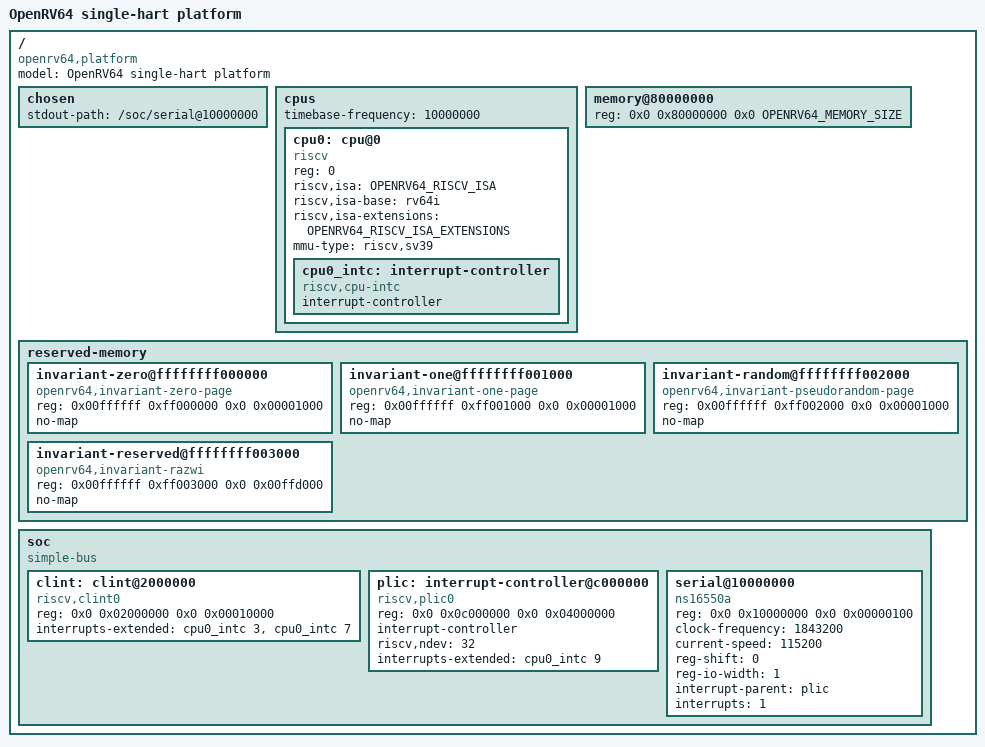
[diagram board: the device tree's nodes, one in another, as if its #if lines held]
/dts-v1/;

#ifndef OPENRV64_MEMORY_SIZE
#define OPENRV64_MEMORY_SIZE 0x10000000
#endif

#ifndef OPENRV64_HART_COUNT
#define OPENRV64_HART_COUNT 1
#endif

#if OPENRV64_HART_COUNT != 1 && OPENRV64_HART_COUNT != 2 && OPENRV64_HART_COUNT != 4
#error OPENRV64_HART_COUNT must be 1, 2, or 4
#endif

#if defined(OPENRV64_ZBB) && defined(OPENRV64_ZICCLSM)
#define OPENRV64_RISCV_ISA "rv64ima_svade_zbb_zicclsm_zicsr_zifencei"
#define OPENRV64_RISCV_ISA_EXTENSIONS "i", "m", "a", "svade", "zbb", "zicclsm", "zicsr", "zifencei"
#elif defined(OPENRV64_ZBB)
#define OPENRV64_RISCV_ISA "rv64ima_svade_zbb_zicsr_zifencei"
#define OPENRV64_RISCV_ISA_EXTENSIONS "i", "m", "a", "svade", "zbb", "zicsr", "zifencei"
#elif defined(OPENRV64_ZICCLSM)
#define OPENRV64_RISCV_ISA "rv64ima_svade_zicclsm_zicsr_zifencei"
#define OPENRV64_RISCV_ISA_EXTENSIONS "i", "m", "a", "svade", "zicclsm", "zicsr", "zifencei"
#else
#define OPENRV64_RISCV_ISA "rv64ima_svade_zicsr_zifencei"
#define OPENRV64_RISCV_ISA_EXTENSIONS "i", "m", "a", "svade", "zicsr", "zifencei"
#endif

/ {
    #address-cells = <2>;
    #size-cells = <2>;
    compatible = "openrv64,platform";
#if OPENRV64_HART_COUNT == 4
    model = "OpenRV64 four-hart platform";
#elif OPENRV64_HART_COUNT == 2
    model = "OpenRV64 two-hart platform";
#else
    model = "OpenRV64 single-hart platform";
#endif

    chosen {
        stdout-path = "/soc/serial@10000000";
#if OPENRV64_HART_COUNT > 1
        opensbi-config {
            compatible = "opensbi,config";
            cold-boot-harts = <&cpu0>;
        };
#endif
    };

    cpus {
        #address-cells = <1>;
        #size-cells = <0>;
        timebase-frequency = <10000000>;

        cpu0: cpu@0 {
            device_type = "cpu";
            reg = <0>;
            status = "okay";
            compatible = "riscv";
            riscv,isa = OPENRV64_RISCV_ISA;
            riscv,isa-base = "rv64i";
            riscv,isa-extensions = OPENRV64_RISCV_ISA_EXTENSIONS;
            mmu-type = "riscv,sv39";

            cpu0_intc: interrupt-controller {
                #interrupt-cells = <1>;
                interrupt-controller;
                compatible = "riscv,cpu-intc";
            };
        };

#if OPENRV64_HART_COUNT >= 2
        cpu1: cpu@1 {
            device_type = "cpu";
            reg = <1>;
            status = "okay";
            compatible = "riscv";
            riscv,isa = OPENRV64_RISCV_ISA;
            riscv,isa-base = "rv64i";
            riscv,isa-extensions = OPENRV64_RISCV_ISA_EXTENSIONS;
            mmu-type = "riscv,sv39";

            cpu1_intc: interrupt-controller {
                #interrupt-cells = <1>;
                interrupt-controller;
                compatible = "riscv,cpu-intc";
            };
        };
#endif

#if OPENRV64_HART_COUNT == 4
        cpu2: cpu@2 {
            device_type = "cpu";
            reg = <2>;
            status = "okay";
            compatible = "riscv";
            riscv,isa = OPENRV64_RISCV_ISA;
            riscv,isa-base = "rv64i";
            riscv,isa-extensions = OPENRV64_RISCV_ISA_EXTENSIONS;
            mmu-type = "riscv,sv39";

            cpu2_intc: interrupt-controller {
                #interrupt-cells = <1>;
                interrupt-controller;
                compatible = "riscv,cpu-intc";
            };
        };

        cpu3: cpu@3 {
            device_type = "cpu";
            reg = <3>;
            status = "okay";
            compatible = "riscv";
            riscv,isa = OPENRV64_RISCV_ISA;
            riscv,isa-base = "rv64i";
            riscv,isa-extensions = OPENRV64_RISCV_ISA_EXTENSIONS;
            mmu-type = "riscv,sv39";

            cpu3_intc: interrupt-controller {
                #interrupt-cells = <1>;
                interrupt-controller;
                compatible = "riscv,cpu-intc";
            };
        };
#endif
    };

    memory@80000000 {
        device_type = "memory";
        reg = <0x0 0x80000000 0x0 OPENRV64_MEMORY_SIZE>;
    };

#if defined(OPENRV64_3P)
    reserved-memory {
        #address-cells = <2>;
        #size-cells = <2>;
        ranges;

        invariant-zero@ffffffff000000 {
            compatible = "openrv64,invariant-zero-page";
            reg = <0x00ffffff 0xff000000 0x0 0x00001000>;
            no-map;
        };

        invariant-one@ffffffff001000 {
            compatible = "openrv64,invariant-one-page";
            reg = <0x00ffffff 0xff001000 0x0 0x00001000>;
            no-map;
        };

        invariant-random@ffffffff002000 {
            compatible = "openrv64,invariant-pseudorandom-page";
            reg = <0x00ffffff 0xff002000 0x0 0x00001000>;
            no-map;
        };

        invariant-reserved@ffffffff003000 {
            compatible = "openrv64,invariant-razwi";
            reg = <0x00ffffff 0xff003000 0x0 0x00ffd000>;
            no-map;
        };
    };
#endif

    soc {
        #address-cells = <2>;
        #size-cells = <2>;
        compatible = "simple-bus";
        ranges;

        clint: clint@2000000 {
            compatible = "riscv,clint0";
            reg = <0x0 0x02000000 0x0 0x00010000>;
#if OPENRV64_HART_COUNT == 4
            interrupts-extended =
                <&cpu0_intc 3>, <&cpu0_intc 7>,
                <&cpu1_intc 3>, <&cpu1_intc 7>,
                <&cpu2_intc 3>, <&cpu2_intc 7>,
                <&cpu3_intc 3>, <&cpu3_intc 7>;
#elif OPENRV64_HART_COUNT == 2
            interrupts-extended =
                <&cpu0_intc 3>, <&cpu0_intc 7>,
                <&cpu1_intc 3>, <&cpu1_intc 7>;
#else
            interrupts-extended = <&cpu0_intc 3>, <&cpu0_intc 7>;
#endif
        };

        plic: interrupt-controller@c000000 {
            compatible = "riscv,plic0";
            reg = <0x0 0x0c000000 0x0 0x04000000>;
            #interrupt-cells = <1>;
            interrupt-controller;
            riscv,ndev = <32>;
#if OPENRV64_HART_COUNT == 4
            interrupts-extended =
                <&cpu0_intc 9>, <&cpu1_intc 9>,
                <&cpu2_intc 9>, <&cpu3_intc 9>;
#elif OPENRV64_HART_COUNT == 2
            interrupts-extended =
                <&cpu0_intc 9>, <&cpu1_intc 9>;
#else
            interrupts-extended = <&cpu0_intc 9>;
#endif
        };

        serial@10000000 {
            compatible = "ns16550a";
            reg = <0x0 0x10000000 0x0 0x00000100>;
            clock-frequency = <1843200>;
            current-speed = <115200>;
            reg-shift = <0>;
            reg-io-width = <1>;
            interrupt-parent = <&plic>;
            interrupts = <1>;
        };
    };
};
